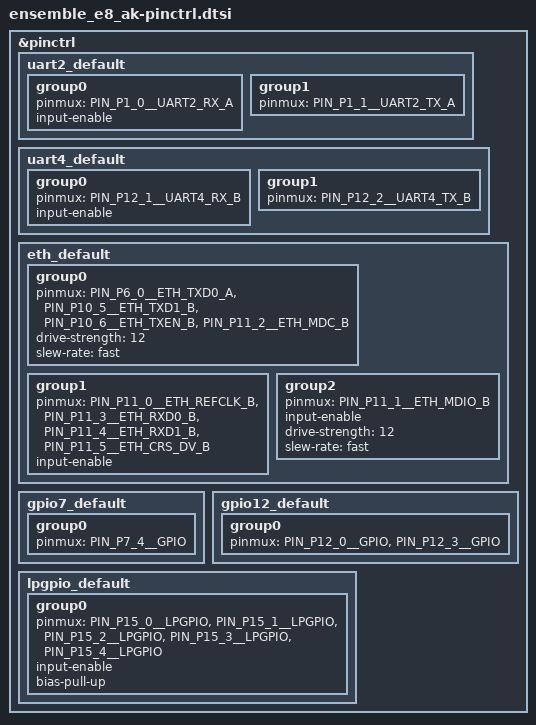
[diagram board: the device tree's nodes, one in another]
/*
 * SPDX-FileCopyrightText: Copyright Alif Semiconductor
 * SPDX-License-Identifier: Apache-2.0
 */

#include <zephyr/dt-bindings/pinctrl/alif-ensemble-pinctrl.h>

&pinctrl {
	uart2_default: uart2_default {
		group0 {
			pinmux = <PIN_P1_0__UART2_RX_A>;
			input-enable;
		};

		group1 {
			pinmux = <PIN_P1_1__UART2_TX_A>;
		};
	};

	uart4_default: uart4_default {
		group0 {
			pinmux = <PIN_P12_1__UART4_RX_B>;
			input-enable;
		};

		group1 {
			pinmux = <PIN_P12_2__UART4_TX_B>;
		};
	};

	eth_default: eth_default {
		group0 {
			/* RMII transmit and MDIO clock to the RTL8201FR PHY */
			pinmux = <PIN_P6_0__ETH_TXD0_A>,
				 <PIN_P10_5__ETH_TXD1_B>,
				 <PIN_P10_6__ETH_TXEN_B>,
				 <PIN_P11_2__ETH_MDC_B>;
			drive-strength = <12>;
			slew-rate = "fast";
		};

		group1 {
			/* From the PHY: the 50 MHz reference clock and the receive signals */
			pinmux = <PIN_P11_0__ETH_REFCLK_B>,
				 <PIN_P11_3__ETH_RXD0_B>,
				 <PIN_P11_4__ETH_RXD1_B>,
				 <PIN_P11_5__ETH_CRS_DV_B>;
			input-enable;
		};

		group2 {
			pinmux = <PIN_P11_1__ETH_MDIO_B>;
			input-enable;
			drive-strength = <12>;
			slew-rate = "fast";
		};
	};

	gpio7_default: gpio7_default {
		group0 {
			/* Multicolor LED0: green on P7_4 */
			pinmux = <PIN_P7_4__GPIO>;
		};
	};

	gpio12_default: gpio12_default {
		group0 {
			/* Multicolor LED0: blue on P12_0, red on P12_3 */
			pinmux = <PIN_P12_0__GPIO>,
				 <PIN_P12_3__GPIO>;
		};
	};

	lpgpio_default: lpgpio_default {
		group0 {
			/* Navigation joystick JOY_SW1 to JOY_SW5 on SW2 */
			pinmux = <PIN_P15_0__LPGPIO>,
				 <PIN_P15_1__LPGPIO>,
				 <PIN_P15_2__LPGPIO>,
				 <PIN_P15_3__LPGPIO>,
				 <PIN_P15_4__LPGPIO>;
			input-enable;
			bias-pull-up;
		};
	};
};
